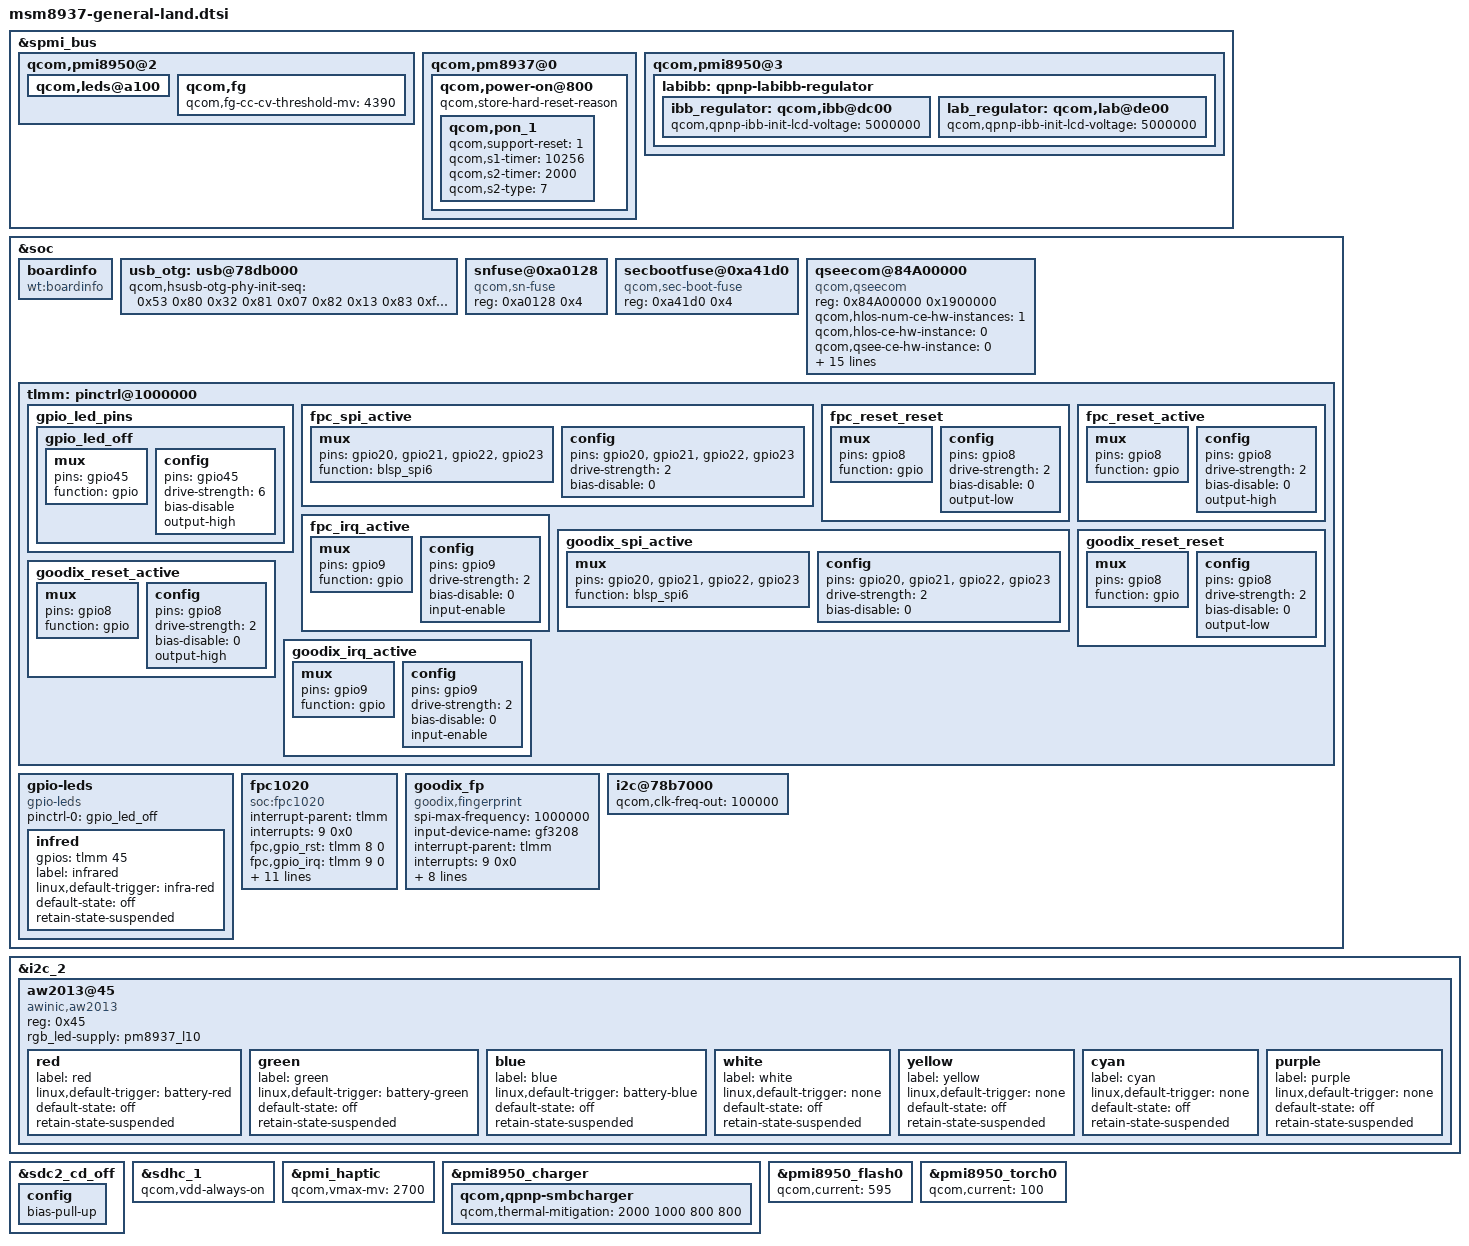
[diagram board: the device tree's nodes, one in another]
/*
 * Copyright (c) 2015-2017, The Linux Foundation. All rights reserved.
 *
 * This program is free software; you can redistribute it and/or modify
 * it under the terms of the GNU General Public License version 2 and
 * only version 2 as published by the Free Software Foundation.
 *
 * This program is distributed in the hope that it will be useful,
 * but WITHOUT ANY WARRANTY; without even the implied warranty of
 * MERCHANTABILITY or FITNESS FOR A PARTICULAR PURPOSE.  See the
 * GNU General Public License for more details.
 */

&spmi_bus {
	qcom,pmi8950@2 {
		qcom,leds@a100 {
			/delete-property/status;
			/delete-node/ qcom,led_mpp_2;
		};

		qcom,fg {
			qcom,fg-cc-cv-threshold-mv = <4390>;
		};
	};

	qcom,pm8937@0 {
		qcom,power-on@800 {
			qcom,store-hard-reset-reason;
			qcom,pon_1 {
				qcom,support-reset = <1>;
				qcom,s1-timer = <10256>;
				qcom,s2-timer = <2000>;
				qcom,s2-type = <7>;
			};
		};
	};

	qcom,pmi8950@3 {
		labibb: qpnp-labibb-regulator {
			ibb_regulator: qcom,ibb@dc00 {
				/delete-property/
					qcom,qpnp-ibb-use-default-voltage;
				qcom,qpnp-ibb-init-lcd-voltage = <5000000>;
			};

			lab_regulator: qcom,lab@de00 {
				/delete-property/
					qcom,qpnp-ibb-use-default-voltage;
				qcom,qpnp-ibb-init-lcd-voltage = <5000000>;
			};
		};
	};
};

&soc {
	boardinfo {
		compatible = "wt:boardinfo";
	};

	usb_otg: usb@78db000 {
		qcom,hsusb-otg-phy-init-seq =
			 <0x53 0x80 0x32 0x81 0x07 0x82 0x13 0x83 0xffffffff>;
	};

	snfuse@0xa0128 {
		compatible = "qcom,sn-fuse";
		reg = <0xa0128 0x4>;
		reg-names = "sn-base";
	};

	secbootfuse@0xa41d0 {
		compatible = "qcom,sec-boot-fuse";
		reg = <0xa41d0 0x4>;
		reg-names = "sec-boot-base";
	};

	qseecom@84A00000 {
		compatible = "qcom,qseecom";
		reg = <0x84A00000 0x1900000>;
		reg-names = "secapp-region";
		qcom,hlos-num-ce-hw-instances = <1>;
		qcom,hlos-ce-hw-instance = <0>;
		qcom,qsee-ce-hw-instance = <0>;
		qcom,disk-encrypt-pipe-pair = <2>;
		qcom,support-fde;
		qcom,appsbl-qseecom-support;
		qcom,msm-bus,name = "qseecom-noc";
		qcom,msm-bus,num-cases = <4>;
		qcom,msm-bus,num-paths = <1>;
		qcom,support-bus-scaling;
		qcom,msm-bus,vectors-KBps =
			<55 512 0 0>,
			<55 512 0 0>,
			<55 512 120000 1200000>,
			<55 512 393600 3936000>;
		clocks = <&clock_gcc clk_crypto_clk_src>,
			 <&clock_gcc clk_gcc_crypto_clk>,
			 <&clock_gcc clk_gcc_crypto_ahb_clk>,
			 <&clock_gcc clk_gcc_crypto_axi_clk>;
		clock-names = "core_clk_src", "core_clk",
				"iface_clk", "bus_clk";
		qcom,ce-opp-freq = <100000000>;
	};
        /delete-node/ qseecom@85b00000;
		
	tlmm: pinctrl@1000000 {
		gpio_led_pins {
			gpio_led_off: gpio_led_off {
				mux {
					pins = "gpio45";
					function = "gpio";
				};
				config {
					pins = "gpio45";
					drive-strength = <6>;
					bias-disable;
					output-high;
				};
			};
		};

		fpc_spi_active: fpc_spi_active{
			mux {
				pins = "gpio20", "gpio21", "gpio22", "gpio23";
				function = "blsp_spi6";
			};
			config {
				pins = "gpio20", "gpio21", "gpio22", "gpio23";
				drive-strength = <2>;
				bias-disable = <0>;
			};
		};

		fpc_reset_reset: fpc_reset_reset{
			mux {
				pins = "gpio8";
				function = "gpio";
			};
			config {
				pins = "gpio8";
				drive-strength = <2>;
				bias-disable = <0>;
				output-low;
			};
		};

		fpc_reset_active: fpc_reset_active{
			mux {
				pins = "gpio8";
				function = "gpio";
			};
			config {
				pins = "gpio8";
				drive-strength = <2>;
				bias-disable = <0>;
				output-high;
			};
		};

		fpc_irq_active: fpc_irq_active {
			mux {
				pins = "gpio9";
				function = "gpio";
			};
			config {
				pins = "gpio9";
				drive-strength = <2>;
				bias-disable = <0>;
				input-enable;
			};
		};

		goodix_spi_active: goodix_spi_active{
			mux {
				pins = "gpio20", "gpio21", "gpio22", "gpio23";
				function = "blsp_spi6";
			};
			config {
				pins = "gpio20", "gpio21", "gpio22", "gpio23";
				drive-strength = <2>;
				bias-disable = <0>;
			};
		};

		goodix_reset_reset: goodix_reset_reset{
			mux {
				pins = "gpio8";
				function = "gpio";
			};
			config {
				pins = "gpio8";
				drive-strength = <2>;
				bias-disable = <0>;
				output-low;
			};
		};

		goodix_reset_active: goodix_reset_active{
			mux {
				pins = "gpio8";
				function = "gpio";
			};
			config {
				pins = "gpio8";
				drive-strength = <2>;
				bias-disable = <0>;
				output-high;
			};
		};

		goodix_irq_active: goodix_irq_active {
			mux {
				pins = "gpio9";
				function = "gpio";
			};
			config {
				pins = "gpio9";
				drive-strength = <2>;
				bias-disable = <0>;
				input-enable;
			};
		};
	};

	gpio-leds {
		compatible = "gpio-leds";
		status = "okay";
		pinctrl-names = "default";
		pinctrl-0 = <&gpio_led_off>;

		infred {
			gpios = <&tlmm 45 0>;
			label = "infrared";
			linux,default-trigger = "infra-red";
			default-state = "off";
			retain-state-suspended;
		};

	};

	fpc1020 {
		compatible = "soc:fpc1020";

		interrupt-parent = <&tlmm>;
		interrupts = <9 0x0>;

		fpc,gpio_rst    = <&tlmm 8 0>;
		fpc,gpio_irq    = <&tlmm 9 0>;

		vcc_spi-supply  = <&pm8937_l5>;
		vdd_ana-supply  = <&pm8937_l5>;
		vdd_io-supply   = <&pm8937_l5>;

		fpc,enable-on-boot;
		/delete-property/
		fpc,enable-wakeup;

		fpc,spi-max-frequency = <4800000>;

		/* Only for SPI Clock Handled by Linux */
		clock-names = "iface_clk", "core_clk";
		clocks = <&clock_gcc clk_gcc_blsp1_ahb_clk>,
				<&clock_gcc clk_gcc_blsp1_qup1_spi_apps_clk>;

		pinctrl-names = "fpc1020_spi_active",
			"fpc1020_reset_reset",
			"fpc1020_reset_active",
			"fpc1020_irq_active";

		pinctrl-0 = <&fpc_spi_active>;
		pinctrl-1 = <&fpc_reset_reset>;
		pinctrl-2 = <&fpc_reset_active>;
		pinctrl-3 = <&fpc_irq_active>;
	};

	goodix_fp {
		compatible = "goodix,fingerprint";
		spi-max-frequency = <1000000>;
		input-device-name = "gf3208";
		interrupt-parent = <&tlmm>;
		interrupts = <9 0x0>;

		goodix,gpio_reset    = <&tlmm 8 0>;
		goodix,gpio_irq      = <&tlmm 9 0>;

		clock-names = "iface_clk", "core_clk";
		clocks = <&clock_gcc clk_gcc_blsp1_ahb_clk>,
				<&clock_gcc clk_gcc_blsp1_qup1_spi_apps_clk>;

		pinctrl-names = "goodixfp_spi_active",
			"goodixfp_reset_reset",
			"goodixfp_reset_active",
			"goodixfp_irq_active";

		pinctrl-0 = <&goodix_spi_active>;
		pinctrl-1 = <&goodix_reset_reset>;
		pinctrl-2 = <&goodix_reset_active>;
		pinctrl-3 = <&goodix_irq_active>;
	};

	i2c@78b7000 {
		qcom,clk-freq-out = <100000>;
		status = "okay";
	};
};

&i2c_2  { /* i2c 6 */
	aw2013@45 { /*blink */
		compatible = "awinic,aw2013";
		reg = <0x45>;
		rgb_led-supply = <&pm8937_l10>;

		red {
			label = "red";
			linux,default-trigger = "battery-red";
			default-state = "off";
			retain-state-suspended;
		};

		green {
			label = "green";
			linux,default-trigger = "battery-green";
			default-state = "off";
			retain-state-suspended;
		};

		blue {
			label = "blue";
			linux,default-trigger = "battery-blue";
			default-state = "off";
			retain-state-suspended;
		};
		white {
			label = "white";
			linux,default-trigger = "none";
			default-state = "off";
			retain-state-suspended;
		};

		yellow {
			label = "yellow";
			linux,default-trigger = "none";
			default-state = "off";
			retain-state-suspended;
		};

		cyan {
			label = "cyan";
			linux,default-trigger = "none";
			default-state = "off";
			retain-state-suspended;
		};

		purple {
			label = "purple";
			linux,default-trigger = "none";
			default-state = "off";
			retain-state-suspended;
		};

	};
};

&sdc2_cd_off {
	config {
		bias-pull-up;
	};
};

&sdhc_1 {
	qcom,vdd-always-on;
};

&pmi_haptic {
	qcom,vmax-mv = <2700>;
};

&pmi8950_charger {
	qcom,qpnp-smbcharger {
			/delete-property/qcom,float-voltage-mv;
			qcom,thermal-mitigation = <2000 1000 800 800>;
			/delete-property/qcom,parallel-usb-min-current-ma;
			/delete-property/qcom,parallel-usb-9v-min-current-ma;
			/delete-property/qcom,parallel-allowed-lowering-ma;
			/delete-property/qcom,autoadjust-vfloat;
	};
};

&pmi8950_flash0 {
		qcom,current = <595>;
};

&pmi8950_torch0 {
		qcom,current = <100>;
};
